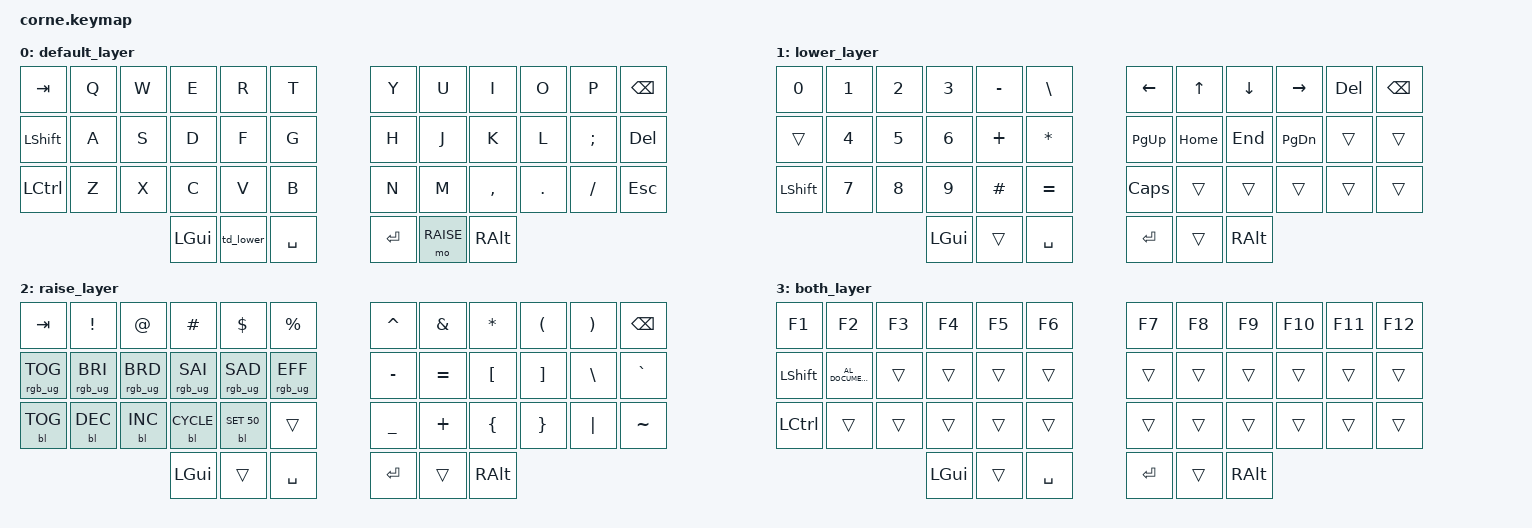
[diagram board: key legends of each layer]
/*
 * Copyright (c) 2020 The ZMK Contributors
 *
 * SPDX-License-Identifier: MIT
 */

#include <behaviors.dtsi>
#include <dt-bindings/zmk/keys.h>
#include <dt-bindings/zmk/bt.h>
#include <dt-bindings/zmk/rgb.h>
#include <dt-bindings/zmk/backlight.h>

#define DEFAULT 0
#define LOWER   1
#define RAISE   2
#define BOTH    3 

/ {

    conditional_layers {
        compatible = "zmk,conditional-layers";
        tri_layer {
            if-layers = <1 2>;
            then-layer = <3>;
        };
    };
	
    behaviors {
        td_lower: tap_dance_lower {
            compatible = "zmk,behavior-tap-dance";
            #binding-cells = <0>;
            tapping-term-ms = <200>; // Tiempo máximo para considerar un tap (toque rápido)
            bindings = <&mo LOWER>, <&tog LOWER>;
        };
    };

    keymap {
			compatible = "zmk,keymap";

			default_layer {
// -----------------------------------------------------------------------------------------
// |  TAB |  Q  |  W  |  E  |  R  |  T  |   |  Y  |  U   |  I  |  O  |  P  | BKSP |
// | SHFT |  A  |  S  |  D  |  F  |  G  |   |  H  |  J   |  K  |  L  |  ;  | supr |
// | CTRL |  Z  |  X  |  C  |  V  |  B  |   |  N  |  M   |  ,  |  .  |  /  | ESC  |
//                    | GUI | LWR | SPC |   | ENT | RSE  | ALT |
						bindings = < 
	&kp TAB &kp Q &kp W &kp E &kp R &kp T &kp Y &kp U &kp I &kp O &kp P &kp BSPC
    &kp LSHFT &kp A &kp S &kp D &kp F &kp G &kp H &kp J &kp K &kp L &kp SEMI &kp DEL
    &kp LCTRL &kp Z &kp X &kp C &kp V &kp B &kp N &kp M &kp COMMA &kp DOT &kp SLASH &kp ESC
            &kp LGUI &td_lower &kp SPACE &kp RET &mo RAISE &kp RALT 
				>;
			};

			lower_layer {
// -----------------------------------------------------------------------------------------
// |  0   |  1  |  2  |  3  |  - |  /  |     |  LFT   |  UP   |DOWN   | RGT   |   DEL | BKSP |
// | CTRL |  4  |  5  |  6  |  + |  *  |     | PG_UP  | HOME  |END    |PG_DN  |       |      |
// | SHFT |  7  |  8  |  9  |  # |  =  |     |CAPSLOCK|       |       |       |       |      |
//                    | GUI |    | SPC |     | ENT |     | ALT |
						bindings = < 
	&kp N0 &kp N1 &kp N2 &kp N3 &kp MINUS &kp BSLH &kp LEFT &kp UP &kp DOWN &kp RIGHT &kp DEL &kp BSPC
    &trans &kp N4 &kp N5 &kp N6 &kp PLUS &kp ASTRK &kp PG_UP &kp HOME &kp END &kp PG_DN &trans &trans
    &kp LSHFT &kp N7 &kp N8 &kp N9 &kp HASH &kp EQUAL  &kp CAPSLOCK  &trans &trans &trans &trans &trans
		&kp LGUI &trans &kp SPACE &kp RET &trans &kp RALT 
						>;
				};

        raise_layer {
            // -----------------------------------------------------------------------------------------
            // |  TAB |  !  |  @  |  #  |  $  |  %  |   |  ^  |  &  |  *  |  (  |  )  | BKSP |
            // | TOG | BRI  | BRD | SAI |SAD |  EFF |   |  -  |  =  |  [  |  ]  |  \  |  `   |
            // | TOG | DEC  | INC |CYCLE|SET |  	|   |  _  |  +  |  {  |  }  | "|" |  ~   |
            //                    | GUI |     | SPC |   | ENT |     | ALT |
            bindings = <
		&kp TAB &kp EXCL &kp AT &kp HASH &kp DLLR &kp PRCNT &kp CARET &kp AMPS &kp ASTRK &kp LPAR &kp RPAR &kp BSPC
        &rgb_ug RGB_TOG &rgb_ug RGB_BRI &rgb_ug RGB_BRD &rgb_ug RGB_SAI &rgb_ug RGB_SAD &rgb_ug RGB_EFF   &kp MINUS &kp EQUAL &kp LBKT &kp RBKT &kp BSLH &kp GRAVE
        &bl BL_TOG &bl BL_DEC &bl BL_INC &bl BL_CYCLE &bl BL_SET 50 &trans  &kp UNDER &kp PLUS &kp LBRC &kp RBRC &kp PIPE &kp TILDE
				&kp LGUI &trans &kp SPACE &kp RET &trans &kp RALT
						>;
        			};
					
        both_layer {
            // -----------------------------------------------------------------------------------------
            // |  F1 |  F2  |  F3 |  F4 | F5 |  F6  |   |  F7 |  F8 |  F9 |  F10 | F11| F12 |
            // | LSHFT |    |     |     |    |      |   |     |     |     |      |    |     |
            // | LCTRL |    |     |     |    |	    |   |     |     |     |      |    |     |
            //                    |     |    |      |   |     |     |     |
            bindings = <
		&kp F1 &kp F2 &kp F3 &kp F4 &kp F5 &kp F6 		&kp F7 &kp F8 &kp F9 &kp F10 &kp F11 &kp F12
        &kp LSHFT &kp C_AL_DOCUMENTS &trans &trans &trans &trans	&trans &trans &trans &trans &trans &trans 
        &kp LCTRL &trans &trans &trans &trans &trans	&trans &trans &trans &trans &trans&trans
						&kp LGUI &trans &kp SPACE 		&kp RET &trans &kp RALT
						>;
        			};
    };
};
